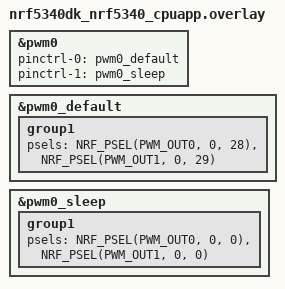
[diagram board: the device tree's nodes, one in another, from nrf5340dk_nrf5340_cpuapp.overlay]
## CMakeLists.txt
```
cmake_minimum_required(VERSION 3.20.0)
find_package(Zephyr REQUIRED HINTS $ENV{ZEPHYR_BASE})

project(pwm-led)

target_sources(app PRIVATE src/main.c)
```

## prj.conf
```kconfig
# Logger module
CONFIG_LOG=y

# Button and LED library
CONFIG_DK_LIBRARY=y

# Bluetooth LE
CONFIG_BT=y
CONFIG_BT_PERIPHERAL=y
CONFIG_BT_DEVICE_NAME="Nordic_PWM_Control"

# Enable LBS Service
CONFIG_BT_LBS=y
CONFIG_BT_LBS_POLL_BUTTON=y

# PWM settings
CONFIG_PWM=y
CONFIG_PWM_LOG_LEVEL_DBG=y

# Increase stack size for the main thread and system workqueue
CONFIG_SYSTEM_WORKQUEUE_STACK_SIZE=2048
CONFIG_MAIN_STACK_SIZE=2048

CONFIG_PINCTRL=y
```

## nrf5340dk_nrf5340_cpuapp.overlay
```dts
&pwm0 {
    status = "okay";
    pinctrl-0 = <&pwm0_default>;
    pinctrl-1 = <&pwm0_sleep>;  // Adding second pin control configuration
    pinctrl-names = "default", "sleep";  // Provide two names as expected
};

&pwm0_default {
    group1 {
        psels = <NRF_PSEL(PWM_OUT0, 0, 28)>, <NRF_PSEL(PWM_OUT1, 0, 29)>; // Configure PWM output on P0.28 and P0.29
    };
};

&pwm0_sleep {
    group1 {
        psels = <NRF_PSEL(PWM_OUT0, 0, 0)>, <NRF_PSEL(PWM_OUT1, 0, 0)>; // Set to unused or disconnected state for sleep mode
    };
};
```

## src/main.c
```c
#include <zephyr/kernel.h>
#include <zephyr/logging/log.h>
#include <zephyr/device.h>
#include <zephyr/drivers/pwm.h>
#include <zephyr/bluetooth/bluetooth.h>
#include <zephyr/bluetooth/gatt.h>

LOG_MODULE_REGISTER(PWM_BLE_Control);

/* Define the PWM device and channels */
#define PWM_NODE DT_NODELABEL(pwm0)
#define PWM_CHANNEL_1 0 // Channel for Motor 1 (P0.28)
#define PWM_CHANNEL_2 1 // Channel for Motor 2 (P0.29)
#define PWM_PERIOD PWM_MSEC(20) // 20 ms (50 Hz)
#define PWM_MIN_PULSE_WIDTH 1000000 // 1 ms for -90°
#define PWM_MAX_PULSE_WIDTH 2000000 // 2 ms for +90°

static const struct device *pwm_dev;

/* Function to set servo motor angle */
static void set_motor(uint8_t motor_num, uint8_t angle) {
    // Clamp angle between 0° and 180°
    if (angle > 180) {
        angle = 180;
    }

    // Calculate pulse width based on angle
    uint32_t pulse_width = PWM_MIN_PULSE_WIDTH +
                           (angle * (PWM_MAX_PULSE_WIDTH - PWM_MIN_PULSE_WIDTH)) / 180;

    int ret;
    if (motor_num == 1) {
        ret = pwm_set(pwm_dev, PWM_CHANNEL_1, PWM_PERIOD, pulse_width, 0);
        if (ret) {
            LOG_ERR("Error setting PWM for Motor 1 (P0.28): %d", ret);
        } else {
            LOG_INF("Motor 1 PWM updated: Angle = %u°, Pulse Width = %u ns", angle, pulse_width);
        }
    } else if (motor_num == 2) {
        ret = pwm_set(pwm_dev, PWM_CHANNEL_2, PWM_PERIOD, pulse_width, 0);
        if (ret) {
            LOG_ERR("Error setting PWM for Motor 2 (P0.29): %d", ret);
        } else {
            LOG_INF("Motor 2 PWM updated: Angle = %u°, Pulse Width = %u ns", angle, pulse_width);
        }
    }
}

/* Function to initialize both motors */
static void initialize_motors(void) {
    LOG_INF("Initializing motors to 90° (center position)");

    // Set both motors to center position
    set_motor(1, 90);
    set_motor(2, 90);
}

/* BLE Write Handlers */
static ssize_t motor1_write_handler(struct bt_conn *conn,
                                    const struct bt_gatt_attr *attr,
                                    const void *buf, uint16_t len,
                                    uint16_t offset, uint8_t flags)
{
    if (len == 1) {
        uint8_t received_angle = *((const uint8_t *)buf);
        LOG_INF("Received angle for Motor 1: %d°", received_angle);
        set_motor(1, received_angle);
    } else {
        LOG_WRN("Unexpected write length for Motor 1: %d", len);
    }
    return len;
}

static ssize_t motor2_write_handler(struct bt_conn *conn,
                                    const struct bt_gatt_attr *attr,
                                    const void *buf, uint16_t len,
                                    uint16_t offset, uint8_t flags)
{
    if (len == 1) {
        uint8_t received_angle = *((const uint8_t *)buf);
        LOG_INF("Received angle for Motor 2: %d°", received_angle);
        set_motor(2, received_angle);
    } else {
        LOG_WRN("Unexpected write length for Motor 2: %d", len);
    }
    return len;
}

/* GATT Service and Characteristics */
BT_GATT_SERVICE_DEFINE(pwm_svc,
    BT_GATT_PRIMARY_SERVICE(BT_UUID_DECLARE_128(
        BT_UUID_128_ENCODE(0x12345678, 0x1234, 0x5678, 0x1234, 0x56789abcdef0))),
    BT_GATT_CHARACTERISTIC(BT_UUID_DECLARE_128(
        BT_UUID_128_ENCODE(0x12345678, 0x1234, 0x5678, 0x1234, 0x56789abcde01)),
        BT_GATT_CHRC_WRITE | BT_GATT_CHRC_WRITE_WITHOUT_RESP,
        BT_GATT_PERM_WRITE,
        NULL, motor1_write_handler, NULL),
    BT_GATT_CHARACTERISTIC(BT_UUID_DECLARE_128(
        BT_UUID_128_ENCODE(0x12345678, 0x1234, 0x5678, 0x1234, 0x56789abcde02)),
        BT_GATT_CHRC_WRITE | BT_GATT_CHRC_WRITE_WITHOUT_RESP,
        BT_GATT_PERM_WRITE,
        NULL, motor2_write_handler, NULL),
);

void on_connected(struct bt_conn *conn, uint8_t err)
{
    if (err) {
        LOG_ERR("Failed to connect (err %d)", err);
        return;
    }
    LOG_INF("Connected to BLE device");
}

void on_disconnected(struct bt_conn *conn, uint8_t reason)
{
    LOG_INF("Disconnected from BLE device (reason %d)", reason);
}

static struct bt_conn_cb conn_callbacks = {
    .connected = on_connected,
    .disconnected = on_disconnected,
};

/* Advertising data */
static const struct bt_data ad[] = {
    BT_DATA_BYTES(BT_DATA_FLAGS, (BT_LE_AD_GENERAL | BT_LE_AD_NO_BREDR)),
    BT_DATA_BYTES(BT_DATA_UUID128_ALL,
        BT_UUID_128_ENCODE(0x12345678, 0x1234, 0x5678, 0x1234, 0x56789abcdef0)),
};

int main(void)
{
    int err;

    LOG_INF("Starting PWM BLE Control for Servo Motors");

    /* Initialize PWM Device */
    pwm_dev = DEVICE_DT_GET(PWM_NODE);
    if (!device_is_ready(pwm_dev)) {
        LOG_ERR("PWM device not ready");
        return -1;
    }
    LOG_INF("PWM device initialized");

    /* Initialize Bluetooth */
    err = bt_enable(NULL);
    if (err) {
        LOG_ERR("Bluetooth initialization failed (err %d)", err);
        return -1;
    }
    LOG_INF("Bluetooth initialized");

    /* Register BLE connection callbacks */
    bt_conn_cb_register(&conn_callbacks);

    /* Start Bluetooth advertising */
    err = bt_le_adv_start(BT_LE_ADV_CONN_NAME, ad, ARRAY_SIZE(ad), NULL, 0);
    if (err) {
        LOG_ERR("Advertising failed to start (err %d)", err);
        return -1;
    }
    LOG_INF("Advertising started");

    /* Initialize both motors */
    initialize_motors();

    LOG_INF("PWM BLE service initialized");

    /* Main loop */
    while (1) {
        k_sleep(K_FOREVER);
    }

    return 0;
}
```
